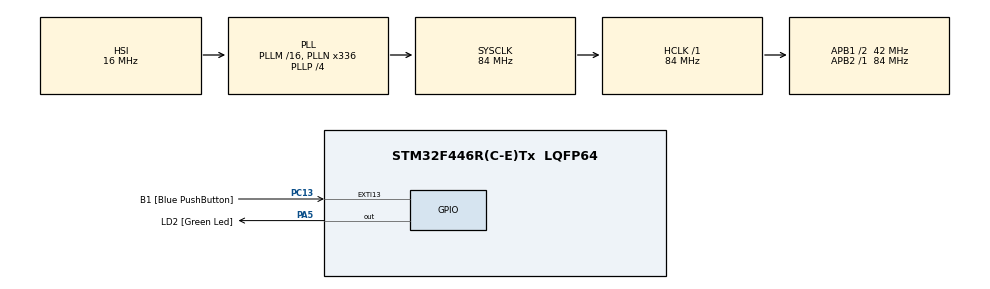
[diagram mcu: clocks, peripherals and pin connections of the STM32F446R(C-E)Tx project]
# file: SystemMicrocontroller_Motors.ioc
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Mcu.Family=STM32F4
PH0-OSC_IN.Signal=RCC_OSC_IN
RCC.CortexFreq_Value=84000000
PC13.Signal=GPXTI13
PA14.GPIO_Label=TCK
PC13.GPIO_Label=B1 [Blue PushButton]
RCC.APB1CLKDivider=RCC_HCLK_DIV2
PC14-OSC32_IN.Signal=RCC_OSC32_IN
RCC.SYSCLKSource=RCC_SYSCLKSOURCE_PLLCLK
ProjectManager.StackSize=0x400
PA13.Signal=SYS_JTMS-SWDIO
ProjectManager.TargetToolchain=STM32CubeIDE
RCC.HCLKFreq_Value=84000000
RCC.APB2TimFreq_Value=84000000
RCC.USBFreq_Value=168000000
RCC.LSE_VALUE=32768
PC15-OSC32_OUT.Signal=RCC_OSC32_OUT
RCC.AHBFreq_Value=84000000
PA5.Signal=GPIO_Output
RCC.HSE_VALUE=8000000
board=NUCLEO-F446RE
RCC.VCOOutputFreq_Value=336000000
RCC.APB2Freq_Value=84000000
PH1-OSC_OUT.Signal=RCC_OSC_OUT
Mcu.Name=STM32F446R(C-E)Tx
PA2.Signal=USART2_TX
PA13.GPIO_Label=TMS
RCC.FLatency-AdvancedSettings=FLASH_LATENCY_2
PB3.Signal=SYS_JTDO-SWO
RCC.SYSCLKFreq_VALUE=84000000
Mcu.Package=LQFP64
PA5.GPIO_Label=LD2 [Green Led]
PC13.GPIO_ModeDefaultEXTI=GPIO_MODE_IT_FALLING
PA2.GPIO_Label=USART_TX
PA14.Signal=SYS_JTCK-SWCLK
ProjectManager.HeapSize=0x200
RCC.HSI_VALUE=16000000
RCC.PLLP=RCC_PLLP_DIV4
NVIC.PriorityGroup=NVIC_PRIORITYGROUP_0
RCC.PLLN=336
RCC.APB1TimFreq_Value=84000000
RCC.APB1Freq_Value=42000000
PA3.GPIO_Label=USART_RX
PA3.Signal=USART2_RX
PB3.GPIO_Label=SWO

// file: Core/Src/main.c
/* USER CODE BEGIN Header */
/**
  ******************************************************************************
  * @file           : main.c
  * @brief          : Main program body
  ******************************************************************************
  * @attention
  *
  * <h2><center>&copy; Copyright (c) 2021 STMicroelectronics.
  * All rights reserved.</center></h2>
  *
  * This software component is licensed by ST under BSD 3-Clause license,
  * the "License"; You may not use this file except in compliance with the
  * License. You may obtain a copy of the License at:
  *                        opensource.org/licenses/BSD-3-Clause
  *
  ******************************************************************************
  */
/* USER CODE END Header */
#include "main.h"

void SystemClock_Config(void);
static void MX_GPIO_Init(void);

int main(void)
{

  /* MCU Configuration--------------------------------------------------------*/

  /* Reset of all peripherals, Initializes the Flash interface and the Systick. */
  HAL_Init();

  /* Configure the system clock */
  SystemClock_Config();

  /* Initialize all configured peripherals */
  MX_GPIO_Init();
  /* USER CODE BEGIN 2 */
  SystemTruckMotors_main();
  /* USER CODE END 2 */

  /* Infinite loop */
  while (1)
  {

  }
}

void SystemClock_Config(void)
{
  RCC_OscInitTypeDef RCC_OscInitStruct = {0};
  RCC_ClkInitTypeDef RCC_ClkInitStruct = {0};

  /** Configure the main internal regulator output voltage
  */
  __HAL_RCC_PWR_CLK_ENABLE();
  __HAL_PWR_VOLTAGESCALING_CONFIG(PWR_REGULATOR_VOLTAGE_SCALE3);
  /** Initializes the RCC Oscillators according to the specified parameters
  * in the RCC_OscInitTypeDef structure.
  */
  RCC_OscInitStruct.OscillatorType = RCC_OSCILLATORTYPE_HSI;
  RCC_OscInitStruct.HSIState = RCC_HSI_ON;
  RCC_OscInitStruct.HSICalibrationValue = RCC_HSICALIBRATION_DEFAULT;
  RCC_OscInitStruct.PLL.PLLState = RCC_PLL_ON;
  RCC_OscInitStruct.PLL.PLLSource = RCC_PLLSOURCE_HSI;
  RCC_OscInitStruct.PLL.PLLM = 16;
  RCC_OscInitStruct.PLL.PLLN = 336;
  RCC_OscInitStruct.PLL.PLLP = RCC_PLLP_DIV4;
  RCC_OscInitStruct.PLL.PLLQ = 2;
  RCC_OscInitStruct.PLL.PLLR = 2;
  if (HAL_RCC_OscConfig(&RCC_OscInitStruct) != HAL_OK)
  {
    Error_Handler();
  }
  /** Initializes the CPU, AHB and APB buses clocks
  */
  RCC_ClkInitStruct.ClockType = RCC_CLOCKTYPE_HCLK|RCC_CLOCKTYPE_SYSCLK
                              |RCC_CLOCKTYPE_PCLK1|RCC_CLOCKTYPE_PCLK2;
  RCC_ClkInitStruct.SYSCLKSource = RCC_SYSCLKSOURCE_PLLCLK;
  RCC_ClkInitStruct.AHBCLKDivider = RCC_SYSCLK_DIV1;
  RCC_ClkInitStruct.APB1CLKDivider = RCC_HCLK_DIV2;
  RCC_ClkInitStruct.APB2CLKDivider = RCC_HCLK_DIV1;

  if (HAL_RCC_ClockConfig(&RCC_ClkInitStruct, FLASH_LATENCY_2) != HAL_OK)
  {
    Error_Handler();
  }
}

static void MX_GPIO_Init(void)
{
  GPIO_InitTypeDef GPIO_InitStruct = {0};

  /* GPIO Ports Clock Enable */
  __HAL_RCC_GPIOC_CLK_ENABLE();
  __HAL_RCC_GPIOH_CLK_ENABLE();
  __HAL_RCC_GPIOA_CLK_ENABLE();
  __HAL_RCC_GPIOB_CLK_ENABLE();

  /*Configure GPIO pin Output Level */
  HAL_GPIO_WritePin(LD2_GPIO_Port, LD2_Pin, GPIO_PIN_RESET);

  /*Configure GPIO pin : B1_Pin */
  GPIO_InitStruct.Pin = B1_Pin;
  GPIO_InitStruct.Mode = GPIO_MODE_IT_FALLING;
  GPIO_InitStruct.Pull = GPIO_NOPULL;
  HAL_GPIO_Init(B1_GPIO_Port, &GPIO_InitStruct);

  /*Configure GPIO pins : USART_TX_Pin USART_RX_Pin */
  GPIO_InitStruct.Pin = USART_TX_Pin|USART_RX_Pin;
  GPIO_InitStruct.Mode = GPIO_MODE_AF_PP;
  GPIO_InitStruct.Pull = GPIO_NOPULL;
  GPIO_InitStruct.Speed = GPIO_SPEED_FREQ_VERY_HIGH;
  GPIO_InitStruct.Alternate = GPIO_AF7_USART2;
  HAL_GPIO_Init(GPIOA, &GPIO_InitStruct);

  /*Configure GPIO pin : LD2_Pin */
  GPIO_InitStruct.Pin = LD2_Pin;
  GPIO_InitStruct.Mode = GPIO_MODE_OUTPUT_PP;
  GPIO_InitStruct.Pull = GPIO_NOPULL;
  GPIO_InitStruct.Speed = GPIO_SPEED_FREQ_LOW;
  HAL_GPIO_Init(LD2_GPIO_Port, &GPIO_InitStruct);

}

void Error_Handler(void)
{
  __disable_irq();
  while (1)
  {
  }
}

#ifdef  USE_FULL_ASSERT
/**
  * @brief  Reports the name of the source file and the source line number
  *         where the assert_param error has occurred.
  * @param  file: pointer to the source file name
  * @param  line: assert_param error line source number
  * @retval None
  */
void assert_failed(uint8_t *file, uint32_t line)
{
  /* USER CODE BEGIN 6 */
	Error_Handler();
  /* User can add his own implementation to report the file name and line number,
     ex: printf("Wrong parameters value: file %s on line %d\r\n", file, line) */
  /* USER CODE END 6 */
}
#endif /* USE_FULL_ASSERT */

/************************ (C) COPYRIGHT STMicroelectronics *****END OF FILE****/
